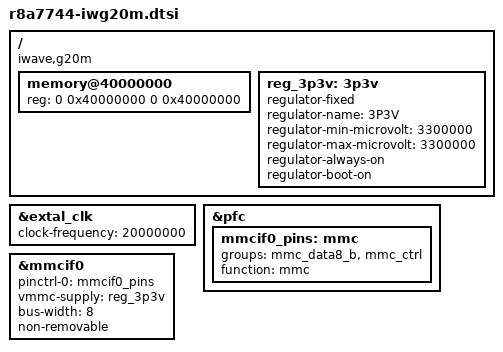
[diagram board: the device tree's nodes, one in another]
// SPDX-License-Identifier: GPL-2.0
/*
 * Device Tree Source for the iWave RZ/G1N Qseven SOM
 *
 * Copyright (C) 2018 Renesas Electronics Corp.
 */

#include "r8a7744.dtsi"
#include <dt-bindings/gpio/gpio.h>

/ {
	compatible = "iwave,g20m", "renesas,r8a7744";

	memory@40000000 {
		device_type = "memory";
		reg = <0 0x40000000 0 0x40000000>;
	};

	reg_3p3v: 3p3v {
		compatible = "regulator-fixed";
		regulator-name = "3P3V";
		regulator-min-microvolt = <3300000>;
		regulator-max-microvolt = <3300000>;
		regulator-always-on;
		regulator-boot-on;
	};
};

&extal_clk {
	clock-frequency = <20000000>;
};

&pfc {
	mmcif0_pins: mmc {
		groups = "mmc_data8_b", "mmc_ctrl";
		function = "mmc";
	};
};

&mmcif0 {
	pinctrl-0 = <&mmcif0_pins>;
	pinctrl-names = "default";

	vmmc-supply = <&reg_3p3v>;
	bus-width = <8>;
	non-removable;
	status = "okay";
};
